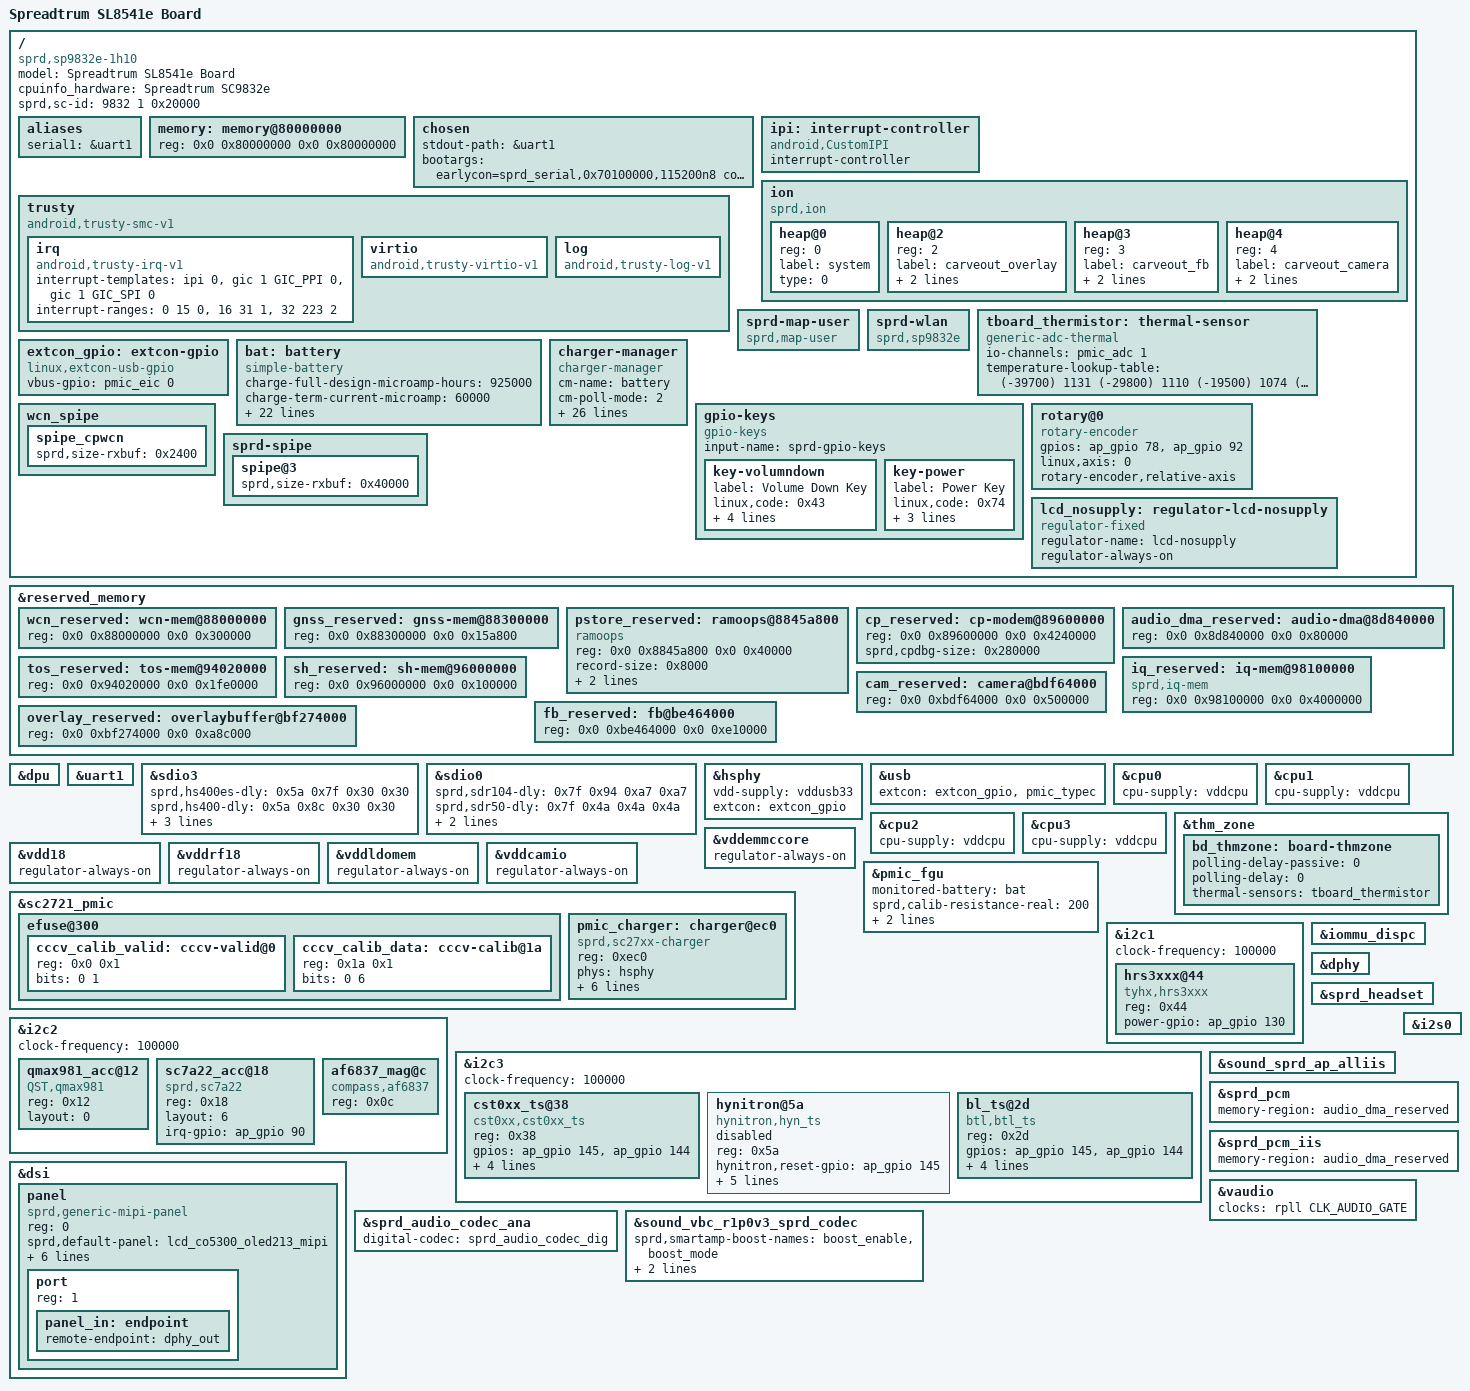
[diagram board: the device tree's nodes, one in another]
/*
 * DM63 watch (SC9832E / SC2721) board DTS for the 4.14 tree
 *
 * Hardware values come from the decompiled stock DT of the watch
 * (devices/dm63/stock.dts of the 4.4 tree). The binding names are the ones
 * the 4.14 drivers read. devices/dm63/DTS_414.md has the node by node table
 * and the open points.
 *
 * Compile only, nothing here has run on a watch.
 *
 * This file is licensed under a dual GPLv2 or X11 license.
 */
/dts-v1/;

#include <dt-bindings/gpio/gpio.h>
#include "sc9832e.dtsi"
#include "sp9832e-mach.dtsi"
#include "sp9832e-watch-firmware.dtsi"
#include "sc9832e-wcn.dtsi"
#include "sc2721.dtsi"
#include "sprd-sound-sharkl.dtsi"
#include "lcd/lcd_co5300_oled1952_mipi.dtsi"
#include "lcd/lcd_co5300_oled206_mipi.dtsi"
#include "lcd/lcd_co5300_oled213_mipi.dtsi"
#include "sp9832e-watch-gpu.dtsi"
#include "sp9832e-watch-gpu-cooling.dtsi"
#include "sp9832e-watch-idle.dtsi"

/ {
	model = "Spreadtrum SL8541e Board";
	compatible = "sprd,sp9832e-1h10", "sprd,sc9832e";
	cpuinfo_hardware = "Spreadtrum SC9832e";
	sprd,sc-id = <9832 1 0x20000>;

	aliases {
		serial1 = &uart1;
	};

	/* stock: memory@80000000, 2 GiB window (MemTotal is lower, see reserved-memory) */
	memory: memory@80000000 {
		device_type = "memory";
		reg = <0x0 0x80000000 0x0 0x80000000>;
	};

	/* bootargs exactly as stock */
	chosen {
		stdout-path = &uart1;
		bootargs = "earlycon=sprd_serial,0x70100000,115200n8 console=ttyS1,115200n8 loglevel=1 init=/init root=/dev/ram0 rw androidboot.hardware=sl8541e_1h10";
	};

	ipi: interrupt-controller {
		compatible = "android,CustomIPI";
		#interrupt-cells = <1>;
		interrupt-controller;
	};

	trusty {
		compatible = "android,trusty-smc-v1";

		irq {
			compatible = "android,trusty-irq-v1";
			interrupt-templates = <&ipi 0>,
						<&gic 1 GIC_PPI 0>,
						<&gic 1 GIC_SPI 0>;
			interrupt-ranges = < 0  15 0>,
						<16  31 1>,
						<32 223 2>;
		};

		virtio {
			compatible = "android,trusty-virtio-v1";
		};

		log {
			compatible = "android,trusty-log-v1";
		};
	};

	/*
	 * stock ion heaps. The 4.14 sprd_ion driver reads reg, label, type and
	 * memory-region of each child. The stock "phys-offset" property is not
	 * read by 4.14 and is dropped.
	 */
	ion {
		compatible = "sprd,ion";
		#address-cells = <1>;
		#size-cells = <0>;

		heap@0 {
			reg = <0>;
			label = "system";
			type = <0>;
		};

		heap@2 {
			reg = <2>;
			label = "carveout_overlay";
			type = <2>;
			memory-region = <&overlay_reserved>;
		};

		heap@3 {
			reg = <3>;
			label = "carveout_fb";
			type = <2>;
			memory-region = <&fb_reserved>;
		};

		heap@4 {
			reg = <4>;
			label = "carveout_camera";
			type = <2>;
			memory-region = <&cam_reserved>;
		};
	};

	/* 4.14 compatible is "sprd,map-user" (stock: "sprd,sprd_map_user") */
	sprd-map-user {
		compatible = "sprd,map-user";
	};

	sprd-wlan {
		compatible = "sprd,sp9832e";
	};

	/*
	 * Board NTC (stock bd-tsensor@10, io-channel 3). The stock channel
	 * numbers are 4.4 logical channels (even = big scale, odd = small
	 * scale, two per hardware channel): 3 -> ADCI1 = hardware channel 1,
	 * which is the 4.14 channel number. Table: stock temp-tab-val (mV) and
	 * temp-tab-temp ((value - 1000) / 10 degC) converted to the
	 * generic-adc-thermal format (mV, milli degC).
	 */
	tboard_thermistor: thermal-sensor {
		compatible = "generic-adc-thermal";
		#thermal-sensor-cells = <0>;
		io-channels = <&pmic_adc 1>;
		io-channel-names = "sensor-channel";
		temperature-lookup-table = <	(-39700) 1131
						(-29800) 1110
						(-19500) 1074
						(-4800) 983
						10100 838
						24800 654
						44900 413
						54900 316
						64900 238
						74900 178
						84900 133
						94900 100
						104900 75
						114900 57
						124900 43 >;
	};

	/*
	 * USB cable detection. Stock: musb "sprd,cable-detection-method" =
	 * "typec", "sprd,vbus-gpios" = PMIC EIC 0 (active high), typec node
	 * mode 2. 4.14 takes both as extcon devices: VBUS from the gpio
	 * extcon, the typec extcon from the PMIC typec block.
	 */
	extcon_gpio: extcon-gpio {
		compatible = "linux,extcon-usb-gpio";
		vbus-gpio = <&pmic_eic 0 GPIO_ACTIVE_HIGH>;
	};

	/*
	 * Battery (stock "battery" node, sprd,sprd-battery) as a simple-battery
	 * with the property names this tree's power_supply_get_battery_info()
	 * reads (note the underscore name of the two constant_charge_* ones).
	 *
	 *   cnom 925 mAh                      charge-full-design-microamp-hours
	 *   rint 360 mOhm                     factory-internal-resistance-micro-ohms
	 *   chg-end-cur 60 mA                 charge-term-current-microamp
	 *   chg-end-vol 4480 mV               constant_charge_voltage_max_microvolt
	 *   alm-vol 3450 mV                   voltage-min-design-microvolt
	 *                                     (low voltage alarm, same role, see SC2721_FGU_MAP.md)
	 *   ocv-tab-vol (mV) / ocv-tab-cap    ocv-capacity-table-0 (uV, percent), 20 degC
	 *   temp-tab-val (mV) / temp-tab-temp voltage-temp-table (uV, deci degC + 1000)
	 *   adp-*-cur / adp-*-cur-limit       charge-*-current-microamp <current limit>
	 *
	 * TODO: stock cnom-temp-tab and rint-temp-tab (capacity and resistance
	 * against temperature) are not mapped: the 4.4 tables are scaled
	 * (cnom 1800/1300/1070/1000 permille, rint 200/450/650/1100 at
	 * 1020/1010/1000/990) and the 4.14 capacity-temp-table and
	 * resistance-temp-table use value / 10 degC, units not proven equal.
	 *
	 * WARNING: 4480 mV is above what sc2720_charger.c programs for the
	 * SC2721 (END_V ceiling 4400 mV), sc2721_set_termination_voltage()
	 * returns -EINVAL and the charger probe fails. See DTS_414.md.
	 */
	bat: battery {
		compatible = "simple-battery";
		charge-full-design-microamp-hours = <925000>;
		charge-term-current-microamp = <60000>;
		constant_charge_voltage_max_microvolt = <4480000>;
		factory-internal-resistance-micro-ohms = <360000>;
		voltage-min-design-microvolt = <3450000>;
		ocv-capacity-celsius = <20>;
		ocv-capacity-table-0 = <4418000 100>, <4356000 95>, <4301000 90>,
				       <4241000 85>, <4182000 80>, <4125000 75>,
				       <4071000 70>, <4019000 65>, <3957000 60>,
				       <3908000 55>, <3874000 50>, <3847000 45>,
				       <3825000 40>, <3806000 35>, <3787000 30>,
				       <3765000 25>, <3745000 20>, <3719000 15>,
				       <3695000 10>, <3677000 5>, <3400000 0>;
		voltage-temp-table = <1052000 750>, <953000 800>, <858000 850>,
				     <762000 900>, <671000 950>, <584000 1000>,
				     <504000 1050>, <434000 1100>, <372000 1150>,
				     <318000 1200>, <271000 1250>, <234000 1300>,
				     <198000 1350>, <165000 1400>, <140000 1450>,
				     <119000 1500>, <104000 1550>, <88000 1600>;
		charge-sdp-current-microamp = <450000 500000>;
		charge-dcp-current-microamp = <450000 3000000>;
		charge-cdp-current-microamp = <450000 1500000>;
		charge-unknown-current-microamp = <430000 500000>;
	};

	/*
	 * charger-manager (psy based in this tree, no regulator child: the
	 * charger is the internal SC2721 one and is started by the charger
	 * driver and by STATUS writes from charger-manager).
	 * [stock] = value derived from the stock battery node, [base] = value
	 * of the 4.14 sl8541e-1h10 reference board, no stock equivalent.
	 *
	 * cm-jeita-temp-table: the five entry stock table, converted in
	 * devices/dm63/DTS_414.md. As in the stock 4.4 sprd_battery.c, every
	 * zone current is capped to the adapter current by the charger
	 * (sc2720_charger_set_current()); the stock 0x7fff (no limit) zone is
	 * written as 32767 mA so the adapter current applies.
	 * cm-wdt-interval is left out: stock chg-wdt is disabled and the
	 * charger driver has no watchdog property.
	 */
	charger-manager {
		compatible = "charger-manager";
		cm-name = "battery";
		cm-poll-mode = <2>;			/* [base] */
		cm-poll-interval = <15000>;		/* [base] */
		cm-battery-stat = <2>;			/* [base] fuel gauge PRESENT (always 1 here) */

		cm-fullbatt-vchkdrop-ms = <30000>;	/* [base] */
		/* [stock] recharge: chg-end-vol-check - rechg-vol = 4450 - 4415 mV */
		cm-fullbatt-vchkdrop-volt = <35000>;
		cm-fullbatt-voltage = <4450000>;	/* [stock] chg-end-vol-check */
		cm-fullbatt-current = <60000>;		/* [stock] chg-end-cur */
		cm-fullbatt-capacity = <100>;		/* [base] */

		cm-num-chargers = <1>;
		cm-chargers = "sc2721_charger";
		cm-fuel-gauge = "sc27xx-fgu";

		/* [stock] outer limits of jeita-temp-tab: -10 and 50 degC, 3 degC hysteresis */
		cm-jeita-temp-table = <900 930 0 4450000>,
				      <1000 1030 100000 4450000>,
				      <1100 1130 500000 4450000>,
				      <1450 1420 32767000 4450000>,
				      <1500 1470 700000 4450000>;

		cm-battery-cold = <100>;
		cm-battery-cold-in-minus;
		cm-battery-hot = <500>;
		cm-battery-temp-diff = <30>;

		cm-charging-max = <21600000>;		/* [stock] chg-timeout 21600 s */
		cm-discharging-max = <2700000>;		/* [base] */

		cm-shutdown-voltage = <3050000>;	/* [stock] soft-vbat-uvlo */
		cm-tickle-time-out = <1500>;		/* [base] */
		cm-one-cap-time = <30>;			/* [stock] cap-one-per-time */

		cm-charge-voltage-max = <6500000>;	/* [stock] ovp-stop */
		cm-charge-voltage-drop = <700000>;	/* [stock] ovp-stop - ovp-restart (6500 - 5800) */
	};

	/*
	 * stock gpio-keys. The 4.14 gpio_keys reads gpio-key,wakeup and
	 * debounce-interval; gpio-key,level-trigger is not read (4.14 takes the
	 * trigger from the gpio, both edges) and is kept for reference only.
	 * linux,code values are the stock ones (0x43 = 67, 0x74 = 116).
	 */
	gpio-keys {
		compatible = "gpio-keys";
		input-name = "sprd-gpio-keys";

		key-volumndown {
			label = "Volume Down Key";
			linux,code = <0x43>;
			/* stock: ap-eic (40210000) pin 2 = debounce EIC channel 2 */
			gpios = <&eic_debounce 2 GPIO_ACTIVE_LOW>;
			debounce-interval = <50>;
			gpio-key,wakeup;
			gpio-key,level-trigger;
		};

		key-power {
			label = "Power Key";
			linux,code = <0x74>;
			gpios = <&pmic_eic 1 GPIO_ACTIVE_LOW>;
			gpio-key,wakeup;
			gpio-key,level-trigger;
		};
	};

	/* stock rotary crown, mainline rotary-encoder binding */
	rotary@0 {
		compatible = "rotary-encoder";
		gpios = <&ap_gpio 78 GPIO_ACTIVE_HIGH>,
			<&ap_gpio 92 GPIO_ACTIVE_HIGH>;
		linux,axis = <0>;
		rotary-encoder,relative-axis;
	};
};

/*
 * SIPC pipes. sc9832e-wcn.dtsi / sc9832e-modem.dtsi carry the same layout as
 * stock except two ring buffer sizes (base values 0x1000 and 0x20000, the
 * latter with a comment that says 256 KiB); stock values used.
 */
/ {
	wcn_spipe {
		spipe_cpwcn {
			sprd,size-rxbuf = <0x2400>;
		};
	};

	sprd-spipe {
		spipe@3 {
			sprd,size-rxbuf = <0x40000>;	/* sdiag_lte */
		};
	};
};

/*
 * reserved-memory: addresses and sizes copied from the stock DT. The
 * sl8541e/mach.dtsi layout (1 GiB board) differs, so the nodes that differ are
 * deleted and declared again with the same labels.
 *
 * Stock has no logo buffer: logo_reserved (0x9e000000, mach.dtsi) and the
 * dpu "sprd,logo-memory" property that points at it are removed (the driver
 * only prints "no sprd,logo-memory specified"). TODO with the display step.
 */
/delete-node/ &logo_reserved;
/delete-node/ &wcn_reserved;
/delete-node/ &gnss_reserved;
/delete-node/ &cp_reserved;
/delete-node/ &iq_reserved;
/delete-node/ &tos_reserved;
/delete-node/ &pstore_reserved;

&reserved_memory {
	wcn_reserved: wcn-mem@88000000 {
		reg = <0x0 0x88000000 0x0 0x300000>;
	};

	gnss_reserved: gnss-mem@88300000 {
		reg = <0x0 0x88300000 0x0 0x15a800>;
	};

	/* ramoops lives here in stock (ramoops node memory-region = pstore) */
	pstore_reserved: ramoops@8845a800 {
		compatible = "ramoops";
		reg = <0x0 0x8845a800 0x0 0x40000>;
		record-size = <0x8000>;
		console-size = <0x8000>;
		pmsg-size = <0x8000>;
	};

	/* stock size includes the 0x280000 debug region (sprd,cpdbg-size) */
	cp_reserved: cp-modem@89600000 {
		reg = <0x0 0x89600000 0x0 0x4240000>;
		sprd,cpdbg-size = <0x280000>;
	};

	audio_dma_reserved: audio-dma@8d840000 {
		reg = <0x0 0x8d840000 0x0 0x80000>;
	};

	tos_reserved: tos-mem@94020000 {
		reg = <0x0 0x94020000 0x0 0x1fe0000>;
	};

	sh_reserved: sh-mem@96000000 {
		reg = <0x0 0x96000000 0x0 0x100000>;
	};

	iq_reserved: iq-mem@98100000 {
		compatible = "sprd,iq-mem";
		reg = <0x0 0x98100000 0x0 0x4000000>;
	};

	cam_reserved: camera@bdf64000 {
		reg = <0x0 0xbdf64000 0x0 0x500000>;
	};

	fb_reserved: fb@be464000 {
		reg = <0x0 0xbe464000 0x0 0xe10000>;
	};

	overlay_reserved: overlaybuffer@bf274000 {
		reg = <0x0 0xbf274000 0x0 0xa8c000>;
	};
};

&dpu {
	/delete-property/ sprd,logo-memory;
	status = "okay";
};

&uart1 {
	status = "okay";
};

/*
 * eMMC (stock sdio@20600000) and SD (sdio@20300000). The 4.14 driver names
 * (sprd,sdhc-r10, sprd,*-dly, sprd,sdio-adma) are the same as stock. Delays,
 * bus width, caps and supplies are the stock ones (mach.dtsi carries the
 * reference board delays for the eMMC, overridden here).
 */
&sdio3 {
	sprd,hs400es-dly = <0x5a 0x7f 0x30 0x30>;
	sprd,hs400-dly = <0x5a 0x8c 0x30 0x30>;
	sprd,hs200-dly = <0x7f 0x8c 0x8e 0x8e>;
	sprd,ddr52-dly = <0x9f 0xb3 0x1e 0x1e>;
	vmmc-supply = <&vddemmccore>;
};

&sdio0 {
	sprd,sdr104-dly = <0x7f 0x94 0xa7 0xa7>;
	sprd,sdr50-dly = <0x7f 0x4a 0x4a 0x4a>;
	vmmc-supply = <&vddsdcore>;
	vqmmc-supply = <&vddsdio>;
};

/*
 * USB. Stock: sprd,usb (musb), dr-mode "peripheral", phy sprd,usb-phy with
 * tune-value 0x5af33, vdd-voltage 3300000 and vdd-supply = vddusb33. 4.14:
 * sprd,sharkle-musb / sprd,sharkle-phy (already in sharkle.dtsi, same
 * tune-value and vdd-voltage). The 4.14 musb takes its mode from Kconfig
 * (dr-mode is not read) and the cable from extcon.
 *
 * TODO: no OTG VBUS regulator is mapped (stock has none in the DT), so
 * host mode has no vbus-supply.
 */
&hsphy {
	vdd-supply = <&vddusb33>;
	extcon = <&extcon_gpio>;
};

&usb {
	extcon = <&extcon_gpio>, <&pmic_typec>;
};

&cpu0 {
	cpu-supply = <&vddcpu>;
};

&cpu1 {
	cpu-supply = <&vddcpu>;
};

&cpu2 {
	cpu-supply = <&vddcpu>;
};

&cpu3 {
	cpu-supply = <&vddcpu>;
};

&thm_zone {
	bd_thmzone: board-thmzone {
		polling-delay-passive = <0>;
		polling-delay = <0>;
		thermal-sensors = <&tboard_thermistor>;
	};
};

/*
 * Regulators. Stock marks these "sprd,default-on" (the 4.4 driver switches
 * them on at probe and never again). In 4.14 a regulator that nothing in the
 * DT consumes is switched off in regulator_late_cleanup(), so the ones that
 * stock keeps on and that have no DT consumer here are regulator-always-on.
 * vddemmccore is the boot storage supply and is kept on as well.
 * (vddcpu/vddcore/vddmem/vddgen/vdd28/vdddcxo are always-on in sc2721.dtsi.)
 * vddsdcore, vddsdio and vddusb33 have consumers (sdio0, touch, hsphy).
 *
 * The sl8541e reference board disables vddrf18 and vddldomem; stock DM63
 * keeps both on.
 */
&vddemmccore {
	regulator-always-on;
};

&vdd18 {
	regulator-always-on;
};

&vddrf18 {
	regulator-always-on;
};

&vddldomem {
	regulator-always-on;
};

&vddcamio {
	regulator-always-on;
};

/*
 * PMIC.
 *
 * efuse nvmem cells for the charger. The 4.14 sc27xx efuse driver exposes
 * 32 blocks of 16 bits as a byte addressed nvmem (stride 1, word size 1):
 * a cell "reg = <offset size>" is a byte offset, block N starts at byte
 * 2 * N, and the read returns the block shifted right by 8 * (offset % 2).
 * The core "bits = <bit_offset nbits>" property selects bits inside the cell,
 * and with it set the cell size is rounded up to whole bytes of
 * (bit_offset + nbits).
 *
 *   4.4 stock: valid flag = block 0 bit 0           -> byte offset 0 * 2 = 0x00, bits <0 1>
 *   4.4 stock: BITSINDEX(13, 0), 6 bits (16 bit block, sprd,block-width = 16)
 *                                                   -> byte offset 13 * 2 = 0x1a, bits <0 6>
 *
 * The same byte offsets are used by the existing cells efuse_blk0 (0x0) and
 * cc_cal (0x1a, whole block 13, used by the typec node); the new cells only
 * select the bits the charger needs. sc2720_charger.c reads
 * "cccv_calib_valid" first (BIT(0) must be set, else the 4.4 default 0x20
 * is used) and then "cccv_calib" (6 bits, masked with 0x3f).
 */
&sc2721_pmic {
	efuse@300 {
		cccv_calib_valid: cccv-valid@0 {
			reg = <0x0 0x1>;
			bits = <0 1>;
		};

		cccv_calib_data: cccv-calib@1a {
			reg = <0x1a 0x1>;
			bits = <0 6>;
		};
	};

	/*
	 * Stock charger@ec0 "sprd,sc2721-charger", reg 0xec0. The mfd cell
	 * matches "sprd,sc27xx-charger", the driver "sprd,sc2721-charger".
	 * "phys" is the USB phy the charger driver registers a notifier on.
	 *
	 * sprd,ovp-microvolt: stock battery ovp-stop 0x1964 = 6500 mV, written
	 * to the input OVP field (code 9).
	 *
	 * chg-ovi-gpios / chg-cv-gpios: stock PMIC EIC 6 / 4, both GPIO_ACTIVE_HIGH
	 * (stock flag 0x00). The driver requests both as optional interrupts;
	 * OVP latches POWER_SUPPLY_HEALTH_OVERVOLTAGE and stops charging until
	 * the comparator clears (devices/SC2721_CHARGER_MAP.md). CV is
	 * diagnostic only, see the driver comment.
	 *
	 * TODO (not implemented in the 4.14 driver, stock values): ovp-restart
	 * 5800 mV (the hardware OVP hysteresis is fixed, nothing to program),
	 * chg-timer@0 (irq 7, superseded by cm-charging-max below),
	 * fast-charger@900 (disabled in stock, stays disabled), chg-wdt@80
	 * (disabled in stock), ITERM level (software equivalent is
	 * cm-fullbatt-current above; the 4.4 driver itself only ever writes a
	 * fixed level 0, the mA policy is not board data we can prove).
	 */
	pmic_charger: charger@ec0 {
		compatible = "sprd,sc27xx-charger", "sprd,sc2721-charger";
		reg = <0xec0>;
		phys = <&hsphy>;
		monitored-battery = <&bat>;
		sprd,ovp-microvolt = <6500000>;
		chg-ovi-gpios = <&pmic_eic 6 GPIO_ACTIVE_HIGH>;
		chg-cv-gpios = <&pmic_eic 4 GPIO_ACTIVE_HIGH>;
		nvmem-cells = <&cccv_calib_data>, <&cccv_calib_valid>;
		nvmem-cell-names = "cccv_calib", "cccv_calib_valid";
	};
};

/*
 * Fuel gauge. Stock fgu@a00 (reg 0xa00, irq 3, ocv-type 1) is the base
 * node; compatible order in sc2721.dtsi lists sprd,sc2721-fgu before
 * sprd,sc2720-fgu so the SC2721 match data is used. io-channels of the base
 * node: bat-temp = 0 (stock adc_temp, logical channel 1 = hardware 0) and
 * charge-vol = 14 (stock adc_vchg, logical 36 = hardware 14).
 *
 * rsense-real/spec: stock 200/200, only the ratio is used (1).
 * comp-resistance: stock temp-comp-res 30 mOhm.
 *
 * Stock has no battery detect gpio and treats the battery as present: the
 * inherited bat-detect-gpio (PMIC EIC 9) is deleted, the gauge then reports
 * the battery as always present and requests no detection interrupt.
 */
&pmic_fgu {
	/delete-property/ bat-detect-gpio;
	monitored-battery = <&bat>;
	sprd,calib-resistance-real = <200>;
	sprd,calib-resistance-spec = <200>;
	sprd,comp-resistance-mohm = <30>;
};

/*
 * I2C. Frequencies are the stock ones (i2c0 400k, others 100k).
 *
 * i2c0 (stock: camera sensors 0x20/0x21) and i2c4 (stock: disabled, flash
 * ocp8137 0x63, fan54015 0x6a) stay disabled here. The camera, with i2c0,
 * is in the ADF board (sp9832e-1h10-dm63-adf.dts), whose stock camera HAL
 * the ported 4.4 camera driver serves.
 */
&i2c1 {
	status = "okay";
	clock-frequency = <100000>;

	/* heart rate, stock hrs3xxx@0x44, power-gpio ap_gpio 130 */
	hrs3xxx@44 {
		compatible = "tyhx,hrs3xxx";
		reg = <0x44>;
		power-gpio = <&ap_gpio 130 GPIO_ACTIVE_HIGH>;
	};
};

&i2c2 {
	status = "okay";
	clock-frequency = <100000>;

	/*
	 * stock qmax981_acc@12: layout 0 (layout-qma6100p 5 is not read by the
	 * 4.14 qma6981 port). Only one of the two accelerometers is fitted on
	 * the unit (sc7a22, see SPEC.md); the other probe fails on the missing
	 * ACK, as in stock.
	 */
	qmax981_acc@12 {
		compatible = "QST,qmax981";
		reg = <0x12>;
		layout = <0>;
	};

	/*
	 * stock sc7a22_acc@18: layout 6, irq-gpio ap_gpio 90 (level high,
	 * hand-up interrupt). Raise-to-wake needs the screen state from the
	 * sprd panel notifier (include/linux/sprd_panel_notifier.h).
	 */
	sc7a22_acc@18 {
		compatible = "sprd,sc7a22";
		reg = <0x18>;
		layout = <6>;
		irq-gpio = <&ap_gpio 90 GPIO_ACTIVE_HIGH>;
	};

	/*
	 * stock af6837_mag@0C (compass,af6837): no other stock properties.
	 * Per devices/AF6837_INTERFACE.md the stock DM63 unit has this node
	 * but the driver never ends up bound on the running stock image, i.e.
	 * the chip is probably not fitted on this board; the chip-id check
	 * in the 4.14 driver fails cleanly (-ENODEV) in that case.
	 */
	af6837_mag@c {
		compatible = "compass,af6837";
		reg = <0x0c>;
	};

	/*
	 * No och1970 node: stock DM63 has none (it is a DW100U part,
	 * magnetic,och1970, rst-gpio).
	 */
};

&i2c3 {
	status = "okay";
	clock-frequency = <100000>;

	/*
	 * Touch. Stock cst0xx_ts@38: gpios = <ap_gpio 145 (reset)>, <ap_gpio
	 * 144 (irq)> in this order, vdd_name "vddsdcore", TP_MAX_X 0x19c
	 * (412), TP_MAX_Y 0x1f6 (502). The driver gets the supply with
	 * devm_regulator_get(dev, vdd_name), i.e. the DT property
	 * "<vdd_name>-supply", which stock did not need. The stock
	 * "virtualkeys" property is not read by the 4.14 port.
	 */
	cst0xx_ts@38 {
		compatible = "cst0xx,cst0xx_ts";
		reg = <0x38>;
		gpios = <&ap_gpio 145 GPIO_ACTIVE_HIGH>,
			<&ap_gpio 144 GPIO_ACTIVE_HIGH>;
		vdd_name = "vddsdcore";
		vddsdcore-supply = <&vddsdcore>;
		TP_MAX_X = <412>;
		TP_MAX_Y = <502>;
	};

	/*
	 * stock hynitron@5a (hynitron,hyn_ts, CST9217): same reset and irq
	 * gpios as cst0xx, not fitted on this unit (SPEC.md). Disabled so the
	 * two drivers do not both toggle the shared reset line. Enable for a
	 * DM63 variant with a Hynitron panel.
	 */
	hynitron@5a {
		compatible = "hynitron,hyn_ts";
		reg = <0x5a>;
		hynitron,reset-gpio = <&ap_gpio 145 GPIO_ACTIVE_HIGH>;
		hynitron,irq-gpio = <&ap_gpio 144 GPIO_ACTIVE_HIGH>;
		hynitron,max-touch-number = <5>;
		hynitron,display-coords = <412 502>;
		vdd_name = "vddsdcore";
		vddsdcore-supply = <&vddsdcore>;
		status = "disabled";
	};

	/*
	 * stock bl_ts@2d (btl,btl_ts, Betterlife BL6133/BL6138): gpios =
	 * <ap_gpio 145 (reset)>, <ap_gpio 144 (irq)> in this order, vdd_name
	 * "vddsdcore", TP_MAX_X 0x19c (412), TP_MAX_Y 0x1f6 (502). "virtualkeys" is
	 * not read by the 4.14 btl_ts port. It shares reset and irq with the
	 * other touch nodes and is placed after them; it identifies the chip in
	 * probe and fails with -ENODEV (or -EBUSY while another touch driver
	 * holds the gpios) on a unit with another controller.
	 */
	bl_ts@2d {
		compatible = "btl,btl_ts";
		reg = <0x2d>;
		gpios = <&ap_gpio 145 GPIO_ACTIVE_HIGH>,
			<&ap_gpio 144 GPIO_ACTIVE_HIGH>;
		vdd_name = "vddsdcore";
		vddsdcore-supply = <&vddsdcore>;
		TP_MAX_X = <412>;
		TP_MAX_Y = <502>;
	};
};

/*
 * Display: CO5300 AMOLED (stock lcd_id ID5300213, node lcd5300213@5300213,
 * 412x502, one DSI lane, command mode). dpu, iommu_dispc, dsi and dphy are
 * enabled; the panel timings, init commands and OLED brightness table are in
 * lcd/lcd_co5300_oled*_mipi.dtsi (all three stock CO5300 variants). See
 * devices/dm63/PANEL_414.md.
 *
 * Panel selection, as stock: the bootloader's lcd_id=ID<hex> picks the /lcds
 * node whose sprd,lcd-id matches (ID53001952, ID5300206, ID5300213).
 * lcd_name= still wins; without either, sprd,default-panel applies
 * (lcd_co5300_oled213_mipi, the ID the stock DM63 reports). A wrong variant gives a blank or shifted picture
 * (column window and timing differ), the init commands do not stress the
 * panel supplies.
 *
 * Stock power-on-sequence (gpio level delay-ms) 33 1 20, 50 1 20, 50 0 20,
 * 50 1 50: gpio 33 is avdd-gpio, gpio 50 is reset-gpio, the levels and
 * delays are in sprd,reset-on-sequence of the lcd dtsi.
 *
 * Stock names no panel regulator, but the 4.14 panel driver needs a "power"
 * supply or its probe fails with -ENODEV (no full constraints on this
 * board), so the panel points at a fixed regulator without enable gpio.
 * Needs CONFIG_REGULATOR_FIXED_VOLTAGE (watch_414.fragment).
 *
 * TODO not mapped: stock sprd_backlight (pwm-backlight on pwm@40260020,
 * pwms index 0, period 20000 ns) is not used by the OLED, the brightness is
 * the oled-backlight of the lcd node. pwms stays disabled. AOD
 * (sprd_aod_idle, DCS 0x38/0x39) has no 4.14 port yet.
 */
/ {
	lcd_nosupply: regulator-lcd-nosupply {
		compatible = "regulator-fixed";
		regulator-name = "lcd-nosupply";
		regulator-always-on;
	};
};

&iommu_dispc {
	status = "okay";
};

&dsi {
	status = "okay";
	#address-cells = <1>;
	#size-cells = <0>;

	panel: panel {
		compatible = "sprd,generic-mipi-panel";
		#address-cells = <1>;
		#size-cells = <0>;
		reg = <0>;

		sprd,default-panel = "lcd_co5300_oled213_mipi";
		power-supply = <&lcd_nosupply>;
		avdd-gpio = <&ap_gpio 33 GPIO_ACTIVE_HIGH>;
		/*
		 * Stock power-on-sequence 33 1 20 (avdd, 20 ms) before the reset
		 * pulses; power-off-sequence 50 0 20, 33 0 20 (reset low, then
		 * avdd low).
		 */
		sprd,avdd-on-delay-ms = <20>;
		sprd,avdd-off-delay-ms = <20>;
		sprd,avdd-off-after-reset;
		reset-gpio = <&ap_gpio 50 GPIO_ACTIVE_HIGH>;

		port {
			reg = <1>;
			panel_in: endpoint {
				remote-endpoint = <&dphy_out>;
			};
		};
	};
};

&dphy {
	status = "okay";
};

/*
 * Audio, as in the stock DM63 DT: SC2721 analog codec linked to the sharkle
 * digital codec, VBC card "sprdphone" (the stock audio HAL opens the cards by
 * name: "sprdphone" and "all-i2s", same names as 4.14 and stock), headset
 * and BT SCO i2s0. sprd-sound-sharkl.dtsi carries the card, dai-links and the
 * headset with the stock DM63 values (gpios pmic eic 3/8/12/5/13, adc
 * thresholds, button ranges and codes are identical to stock), so only the
 * enables and the DM63 specifics are set here.
 * Without digital-codec the codec probe fails with -EINVAL ("Parse
 * 'digital-codec' failed") and no sound card registers.
 */
&sprd_audio_codec_ana {
	status = "okay";
	digital-codec = <&sprd_audio_codec_dig>;
};

&sprd_headset {
	status = "okay";
};

/*
 * Speaker boost control gpios: stock sprd,smartamp-boost-gpios is ap gpio
 * 27 (boost_enable) and 85 (boost_mode). The sl8541e board uses 121 and 85.
 */
&sound_vbc_r1p0v3_sprd_codec {
	status = "okay";
	sprd,smartamp-boost-names = "boost_enable", "boost_mode";
	sprd,smartamp-boost-gpios = <&ap_gpio 27 GPIO_ACTIVE_HIGH>,
				    <&ap_gpio 85 GPIO_ACTIVE_HIGH>;
};

&sound_sprd_ap_alliis {
	status = "okay";
};

&i2s0 {
	status = "okay";
};

/*
 * Stock puts the audio dma buffers in the audio_dma@8d840000 reserved region
 * (sprd,dma_use_ddr_reserved, memory-region on both pcm platform nodes). The
 * 4.14 pcm driver switches to the reserved ddr buffer when memory-region is
 * present. The stock vaudio tuned_26m clock is clk_audio_gate (gate bit 8 of
 * 0x40410000), the rpll CLK_AUDIO_GATE output in 4.14.
 */
&sprd_pcm {
	memory-region = <&audio_dma_reserved>;
};

&sprd_pcm_iis {
	memory-region = <&audio_dma_reserved>;
};

&vaudio {
	clocks = <&rpll CLK_AUDIO_GATE>;
	clock-names = "tuned_26m";
};
